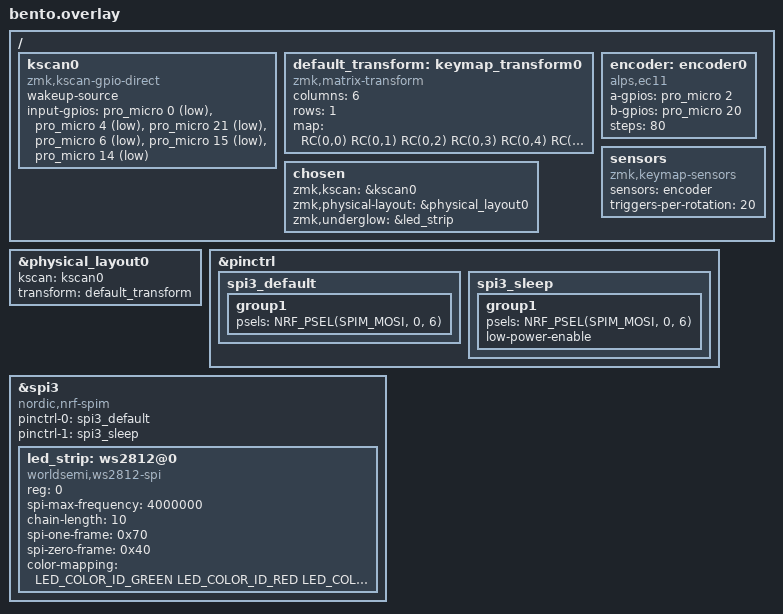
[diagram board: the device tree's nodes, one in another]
#include "bento-layouts.dtsi"
#include <dt-bindings/zmk/matrix_transform.h> // Put this with the other includes at the top of your overlay
#include <dt-bindings/led/led.h>

/ {
    kscan0: kscan0 {
        compatible = "zmk,kscan-gpio-direct";
        wakeup-source;
        input-gpios
            = <&pro_micro 0 (GPIO_ACTIVE_LOW | GPIO_PULL_UP)>
            , <&pro_micro 4 (GPIO_ACTIVE_LOW | GPIO_PULL_UP)>
            , <&pro_micro 21 (GPIO_ACTIVE_LOW | GPIO_PULL_UP)>
            , <&pro_micro 6 (GPIO_ACTIVE_LOW | GPIO_PULL_UP)>
            , <&pro_micro 15 (GPIO_ACTIVE_LOW | GPIO_PULL_UP)>
            , <&pro_micro 14 (GPIO_ACTIVE_LOW | GPIO_PULL_UP)>
            ;
    };

    default_transform: keymap_transform0 {
        compatible = "zmk,matrix-transform";
        columns = <6>; // Length of the "col-gpios" array
        rows = <1>; // Length of the "row-gpios" array
        map = <
        //   Key 1 | Key 2 | Key 3 | Key 4 | Key 5 | Key 6
            RC(0,0) RC(0,1) RC(0,2) RC(0,3) RC(0,4) RC(0,5)
        >;
    };

    encoder: encoder0 {
        compatible = "alps,ec11";
        a-gpios = <&pro_micro 2 (GPIO_ACTIVE_HIGH | GPIO_PULL_UP)>;
        b-gpios = <&pro_micro 20 (GPIO_ACTIVE_HIGH | GPIO_PULL_UP)>;
        steps = <80>;
        status = "disabled";
    };

    sensors {
        compatible = "zmk,keymap-sensors";
        sensors = <&encoder>;
        triggers-per-rotation = <20>;
    };
};

&physical_layout0 {
    kscan = <&kscan0>; // Label of the kscan node this layout uses
    transform = <&default_transform>; // Label of the matrix transform this layout uses
};

&encoder {
    status = "okay";
};

&pinctrl {
    spi3_default: spi3_default {
        group1 {
            psels = <NRF_PSEL(SPIM_MOSI, 0, 6)>;
        };
    };

    spi3_sleep: spi3_sleep {
        group1 {
            psels = <NRF_PSEL(SPIM_MOSI, 0, 6)>;
            low-power-enable;
        };
    };
};

&spi3 {
    compatible = "nordic,nrf-spim";
    status = "okay";

    pinctrl-0 = <&spi3_default>;
    pinctrl-1 = <&spi3_sleep>;
    pinctrl-names = "default", "sleep";

    led_strip: ws2812@0 {
        compatible = "worldsemi,ws2812-spi";

        /* SPI */
        reg = <0>; /* ignored, but necessary for SPI bindings */
        spi-max-frequency = <4000000>;

        /* WS2812 */
        chain-length = <10>; /* number of LEDs */
        spi-one-frame = <0x70>;
        spi-zero-frame = <0x40>;
        color-mapping = <LED_COLOR_ID_GREEN
                         LED_COLOR_ID_RED
                         LED_COLOR_ID_BLUE>;
    };
};

/ {
    chosen {
        zmk,kscan = &kscan0;
        zmk,physical-layout = &physical_layout0;
        // Other chosen items
        zmk,underglow = &led_strip;
    };
};
